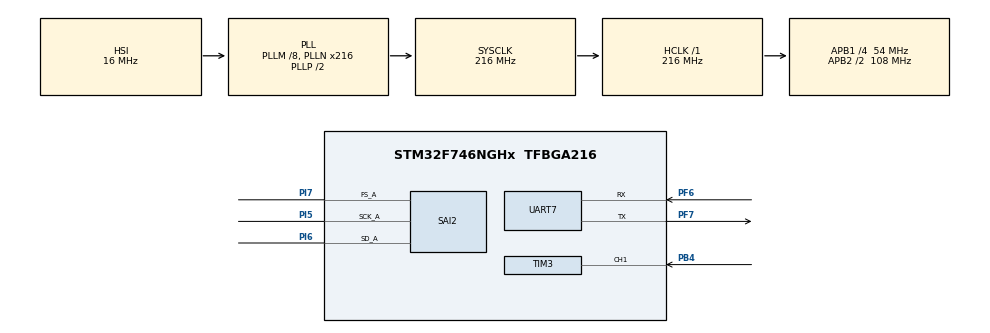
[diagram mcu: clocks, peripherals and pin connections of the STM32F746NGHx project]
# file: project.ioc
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Dma.Request0=SAI2_A
Dma.SAI2_A.0.Direction=DMA_MEMORY_TO_PERIPH
Dma.SAI2_A.0.FIFOMode=DMA_FIFOMODE_DISABLE
Dma.SAI2_A.0.Instance=DMA2_Stream4
Dma.SAI2_A.0.MemDataAlignment=DMA_MDATAALIGN_WORD
Dma.SAI2_A.0.MemInc=DMA_MINC_ENABLE
Dma.SAI2_A.0.Mode=DMA_NORMAL
Dma.SAI2_A.0.PeriphDataAlignment=DMA_PDATAALIGN_WORD
Dma.SAI2_A.0.PeriphInc=DMA_PINC_DISABLE
Dma.SAI2_A.0.Priority=DMA_PRIORITY_LOW
Mcu.Family=STM32F7
Mcu.Name=STM32F746NGHx
Mcu.Package=TFBGA216
NVIC.DMA2_Stream4_IRQn=true\:0\:0\:false\:false\:true\:false\:true
NVIC.PriorityGroup=NVIC_PRIORITYGROUP_4
PB4.Signal=S_TIM3_CH1
PF6.Mode=Asynchronous
PF6.Signal=UART7_RX
PF7.Mode=Asynchronous
PF7.Signal=UART7_TX
PI5.Mode=SAI_A_Master
PI5.Signal=SAI2_SCK_A
PI6.Mode=SAI_A_Master
PI6.Signal=SAI2_SD_A
PI7.Mode=SAI_A_Master
PI7.Signal=SAI2_FS_A
ProjectManager.HeapSize=0x200
ProjectManager.StackSize=0x400
ProjectManager.TargetToolchain=STM32CubeIDE
RCC.AHBFreq_Value=216000000
RCC.APB1CLKDivider=RCC_HCLK_DIV4
RCC.APB1Freq_Value=54000000
RCC.APB1TimFreq_Value=108000000
RCC.APB2CLKDivider=RCC_HCLK_DIV2
RCC.APB2Freq_Value=108000000
RCC.APB2TimFreq_Value=216000000
RCC.CortexFreq_Value=216000000
RCC.HCLKFreq_Value=216000000
RCC.HSE_VALUE=25000000
RCC.HSI_VALUE=16000000
RCC.LSE_VALUE=32768
RCC.PLLM=8
RCC.PLLN=216
RCC.PLLSAIN=50
RCC.PLLSourceVirtual=RCC_PLLSOURCE_HSI
RCC.SYSCLKFreq_VALUE=216000000
RCC.SYSCLKSource=RCC_SYSCLKSOURCE_PLLCLK
RCC.USBFreq_Value=216000000
RCC.VCOOutputFreq_Value=432000000
SAI2.ErrorAudioFreq-SAI_A_Master=56.25 %
SAI2.Instance-SAI_A_Master=SAI$Index_Block_A
SAI2.MClockEnable-SAI_A_Master=SAI_MASTERCLOCK_DISABLE
SAI2.RealAudioFreq-SAI_A_Master=300.0 KHz
SAI2.VirtualMode-SAI_A_Master=VM_MASTER
SH.S_TIM3_CH1.0=TIM3_CH1,Input_Capture1_from_TI1
STMicroelectronics.X-CUBE-AI.4.0.0.ApplicationCcArtificialOoIntelligenceJjApplication=ApplicationTemplate
STMicroelectronics.X-CUBE-AI.4.0.0.ArtificialOoIntelligenceJjApplication.cmp_version0=4.0.0
STMicroelectronics.X-CUBE-AI.4.0.0.ArtificialOoIntelligenceJjApplication.component0=Artificial Intelligence
STMicroelectronics.X-CUBE-AI.4.0.0.ArtificialOoIntelligenceJjApplication.description0=AI Application,Application Template
STMicroelectronics.X-CUBE-AI.4.0.0.ArtificialOoIntelligenceJjApplication.diagnostic0=This component should operate correctly.
STMicroelectronics.X-CUBE-AI.4.0.0.ArtificialOoIntelligenceJjApplication.documentation0=Documentation/index.html
STMicroelectronics.X-CUBE-AI.4.0.0.ArtificialOoIntelligenceJjApplication.group0=Application
STMicroelectronics.X-CUBE-AI.4.0.0.ArtificialOoIntelligenceJjApplication.paramName0=ApplicationCcArtificialOoIntelligenceJjApplication
STMicroelectronics.X-CUBE-AI.4.0.0.ArtificialOoIntelligenceJjApplication.sevirity0=none
STMicroelectronics.X-CUBE-AI.4.0.0.ArtificialOoIntelligenceJjApplication.variant0=ApplicationTemplate
STMicroelectronics.X-CUBE-AI.4.0.0.ArtificialOoIntelligenceJjApplication_bundle=Application
STMicroelectronics.X-CUBE-AI.4.0.0.ArtificialOoIntelligenceJjApplication_class=ArtificialOoIntelligence
STMicroelectronics.X-CUBE-AI.4.0.0.ArtificialOoIntelligenceJjApplication_name=X-CUBE-AI
STMicroelectronics.X-CUBE-AI.4.0.0.ArtificialOoIntelligenceJjApplication_size=1
STMicroelectronics.X-CUBE-AI.4.0.0.ArtificialOoIntelligenceJjApplication_vendor=STMicroelectronics
STMicroelectronics.X-CUBE-AI.4.0.0.ArtificialOoIntelligenceJjApplication_version=4.0.0
STMicroelectronics.X-CUBE-AI.4.0.0.ArtificialOoIntelligenceJjXAaCUBEAaAI.cmp_version0=4.0.0
STMicroelectronics.X-CUBE-AI.4.0.0.ArtificialOoIntelligenceJjXAaCUBEAaAI.cmp_version1=4.0.0
STMicroelectronics.X-CUBE-AI.4.0.0.ArtificialOoIntelligenceJjXAaCUBEAaAI.component0=Artificial Intelligence
STMicroelectronics.X-CUBE-AI.4.0.0.ArtificialOoIntelligenceJjXAaCUBEAaAI.component1=Artificial Intelligence
STMicroelectronics.X-CUBE-AI.4.0.0.ArtificialOoIntelligenceJjXAaCUBEAaAI.componentDoc0=nofile
STMicroelectronics.X-CUBE-AI.4.0.0.ArtificialOoIntelligenceJjXAaCUBEAaAI.description0=AI Core,Artificial Intelligence for STM32
STMicroelectronics.X-CUBE-AI.4.0.0.ArtificialOoIntelligenceJjXAaCUBEAaAI.description1=AI Application,Application Template
STMicroelectronics.X-CUBE-AI.4.0.0.ArtificialOoIntelligenceJjXAaCUBEAaAI.diagnostic0=This component should operate correctly.
STMicroelectronics.X-CUBE-AI.4.0.0.ArtificialOoIntelligenceJjXAaCUBEAaAI.diagnostic1=This component should operate correctly.
STMicroelectronics.X-CUBE-AI.4.0.0.ArtificialOoIntelligenceJjXAaCUBEAaAI.documentation0=Documentation/index.html
STMicroelectronics.X-CUBE-AI.4.0.0.ArtificialOoIntelligenceJjXAaCUBEAaAI.documentation1=Documentation/index.html
STMicroelectronics.X-CUBE-AI.4.0.0.ArtificialOoIntelligenceJjXAaCUBEAaAI.group0=Core
STMicroelectronics.X-CUBE-AI.4.0.0.ArtificialOoIntelligenceJjXAaCUBEAaAI.group1=Application
STMicroelectronics.X-CUBE-AI.4.0.0.ArtificialOoIntelligenceJjXAaCUBEAaAI.paramName0=XAaCUBEAaAICcArtificialOoIntelligenceJjCore
STMicroelectronics.X-CUBE-AI.4.0.0.ArtificialOoIntelligenceJjXAaCUBEAaAI.paramName1=ApplicationCcArtificialOoIntelligenceJjApplication
STMicroelectronics.X-CUBE-AI.4.0.0.ArtificialOoIntelligenceJjXAaCUBEAaAI.sevirity0=none
STMicroelectronics.X-CUBE-AI.4.0.0.ArtificialOoIntelligenceJjXAaCUBEAaAI.sevirity1=none
STMicroelectronics.X-CUBE-AI.4.0.0.ArtificialOoIntelligenceJjXAaCUBEAaAI.variant1=ApplicationTemplate
STMicroelectronics.X-CUBE-AI.4.0.0.ArtificialOoIntelligenceJjXAaCUBEAaAI_bundle=X-CUBE-AI
STMicroelectronics.X-CUBE-AI.4.0.0.ArtificialOoIntelligenceJjXAaCUBEAaAI_class=ArtificialOoIntelligence
STMicroelectronics.X-CUBE-AI.4.0.0.ArtificialOoIntelligenceJjXAaCUBEAaAI_name=X-CUBE-AI
STMicroelectronics.X-CUBE-AI.4.0.0.ArtificialOoIntelligenceJjXAaCUBEAaAI_size=2
STMicroelectronics.X-CUBE-AI.4.0.0.ArtificialOoIntelligenceJjXAaCUBEAaAI_vendor=STMicroelectronics
STMicroelectronics.X-CUBE-AI.4.0.0.ArtificialOoIntelligenceJjXAaCUBEAaAI_version=4.0.0
STMicroelectronics.X-CUBE-AI.4.0.0.LatestDirectoryUsed-ff25e316b0d218b1b75e30100dc37cf2b87ceea797e5b8a9c0dbcca06200be8c=/Users/andersliss/Google Drive/Dokument/Resurser/Python/50ms_30mels
STMicroelectronics.X-CUBE-AI.4.0.0.ModelActualCompression-ff25e316b0d218b1b75e30100dc37cf2b87ceea797e5b8a9c0dbcca06200be8c=0.0
STMicroelectronics.X-CUBE-AI.4.0.0.ModelCompression-ff25e316b0d218b1b75e30100dc37cf2b87ceea797e5b8a9c0dbcca06200be8c=1
STMicroelectronics.X-CUBE-AI.4.0.0.ModelFlashOccupation-ff25e316b0d218b1b75e30100dc37cf2b87ceea797e5b8a9c0dbcca06200be8c=11368
STMicroelectronics.X-CUBE-AI.4.0.0.ModelHashList=ff25e316b0d218b1b75e30100dc37cf2b87ceea797e5b8a9c0dbcca06200be8c
STMicroelectronics.X-CUBE-AI.4.0.0.ModelKind-ff25e316b0d218b1b75e30100dc37cf2b87ceea797e5b8a9c0dbcca06200be8c=KERAS
STMicroelectronics.X-CUBE-AI.4.0.0.ModelMacc-ff25e316b0d218b1b75e30100dc37cf2b87ceea797e5b8a9c0dbcca06200be8c=491910
STMicroelectronics.X-CUBE-AI.4.0.0.ModelName-ff25e316b0d218b1b75e30100dc37cf2b87ceea797e5b8a9c0dbcca06200be8c=network_multitest
STMicroelectronics.X-CUBE-AI.4.0.0.ModelNameList=network_multitest
STMicroelectronics.X-CUBE-AI.4.0.0.ModelRamOccupation-ff25e316b0d218b1b75e30100dc37cf2b87ceea797e5b8a9c0dbcca06200be8c=144000
STMicroelectronics.X-CUBE-AI.4.0.0.ModelStructureFile-ff25e316b0d218b1b75e30100dc37cf2b87ceea797e5b8a9c0dbcca06200be8c=/Users/andersliss/Google Drive/Dokument/Resurser/Python/50ms_30mels/DNN_Model.h5
STMicroelectronics.X-CUBE-AI.4.0.0.ModelType-ff25e316b0d218b1b75e30100dc37cf2b87ceea797e5b8a9c0dbcca06200be8c=Saved model
STMicroelectronics.X-CUBE-AI.4.0.0.ValidationInputFile-ff25e316b0d218b1b75e30100dc37cf2b87ceea797e5b8a9c0dbcca06200be8c=/Users/andersliss/Google Drive/Dokument/Resurser/Python/100ms_nomels/x_50ms_val.csv
STMicroelectronics.X-CUBE-AI.4.0.0.ValidationOutputFile-ff25e316b0d218b1b75e30100dc37cf2b87ceea797e5b8a9c0dbcca06200be8c=/Users/andersliss/Google Drive/Dokument/Resurser/Python/100ms_nomels/y_50ms_val.csv
STMicroelectronics.X-CUBE-AI.4.0.0.XAaCUBEAaAICcArtificialOoIntelligenceJjCore=true
STMicroelectronics.X-CUBE-AI.4.0.0_ArtificialOoIntelligenceJjApplication_RteComponent0=\#define AI_ApplicationTemplate
STMicroelectronics.X-CUBE-AI.4.0.0_ArtificialOoIntelligenceJjApplication_RteComponentsize=1
STMicroelectronics.X-CUBE-AI.4.0.0_ArtificialOoIntelligenceJjXAaCUBEAaAI_RteComponentsize=0
STMicroelectronics.X-CUBE-AI.4.0.0_MwName0=X-CUBE-AI
STMicroelectronics.X-CUBE-AI.4.0.0_MwName1=Application
STMicroelectronics.X-CUBE-AI.4.0.0_NumberOfMw=2
STMicroelectronics.X-CUBE-AI.4.0.0_description=Artificial Intelligence
STMicroelectronics.X-CUBE-AI.4.0.0_license=SLA0048.txt
TIM3.Channel-Input_Capture1_from_TI1=TIM_CHANNEL_1
VP_CRC_VS_CRC.Mode=CRC_Activate
VP_STMicroelectronics.X-CUBE-AI_VS_ArtificialOoIntelligenceJjApplication_4.0.0.Mode=ArtificialOoIntelligenceJjApplication
VP_STMicroelectronics.X-CUBE-AI_VS_ArtificialOoIntelligenceJjXAaCUBEAaAI_4.0.0.Mode=ArtificialOoIntelligenceJjXAaCUBEAaAI
VP_TIM3_VS_ClockSourceINT.Mode=Internal
board=STM32F746G-DISCO

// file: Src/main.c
/* USER CODE BEGIN Header */
/**
  ******************************************************************************
  * @file           : main.c
  * @brief          : Main program body
  ******************************************************************************
  * @attention
  *
  * <h2><center>&copy; Copyright (c) 2019 STMicroelectronics.
  * All rights reserved.</center></h2>
  *
  * This software component is licensed by ST under BSD 3-Clause license,
  * the "License"; You may not use this file except in compliance with the
  * License. You may obtain a copy of the License at:
  *                        opensource.org/licenses/BSD-3-Clause
  *
  ******************************************************************************
  */
/* USER CODE END Header */

#include "main.h"
#include "app_x-cube-ai.h"

/* USER CODE BEGIN Includes */
#include "audio_processing.h"
/* USER CODE END Includes */

CRC_HandleTypeDef hcrc;

SAI_HandleTypeDef hsai_BlockA2;
DMA_HandleTypeDef hdma_sai2_a;

TIM_HandleTypeDef htim3;

UART_HandleTypeDef huart7;

/* USER CODE BEGIN PV */
uint16_t input[buffersize] = {0};
uint16_t *pInput = &input[0];
uint16_t processbuffer[buffersize] = {0};
float32_t fftbuf[buffersize] = {0};
uint8_t check = 0;

/* USER CODE END PV */

void SystemClock_Config(void);
static void MX_GPIO_Init(void);
static void MX_DMA_Init(void);
static void MX_CRC_Init(void);
static void MX_SAI2_Init(void);
static void MX_TIM3_Init(void);
static void MX_UART7_Init(void);

int main(void)
{

  /* MCU Configuration--------------------------------------------------------*/

  /* Reset of all peripherals, Initializes the Flash interface and the Systick. */
  HAL_Init();

  /* Configure the system clock */
  SystemClock_Config();

  /* Initialize all configured peripherals */
  MX_GPIO_Init();
  MX_DMA_Init();
  MX_CRC_Init();
  MX_SAI2_Init();
  MX_TIM3_Init();
  MX_UART7_Init();
  MX_X_CUBE_AI_Init();
  /* USER CODE BEGIN 2 */

  // Initialize audio input with BSP
  BSP_AUDIO_IN_InitEx(INPUT_DEVICE_DIGITAL_MICROPHONE_2, 44100, 16, 1);
  BSP_AUDIO_IN_Record(pInput, buffersize);

  // Initializing spectrogram
  Spectro_Init();

  /* USER CODE END 2 */

  /* Infinite loop */
  while (1)
  {

    /* USER CODE BEGIN 3 */
		 // Copy input memory to processing buffer
	  memcpy(&processbuffer[0],&input[0],buffersize);

	 // Convert uint16_t to float32 for use with CMSIS
	  for (uint16_t c = 0; c < buffersize; c++)
	  {
		  fftbuf[c] = (float32_t)processbuffer[c];
	  }

	  Spectrogram_Run((float32_t *) fftbuf);
	  check = 1;
  }
  /* USER CODE END 3 */
}

void SystemClock_Config(void)
{
  RCC_OscInitTypeDef RCC_OscInitStruct = {0};
  RCC_ClkInitTypeDef RCC_ClkInitStruct = {0};
  RCC_PeriphCLKInitTypeDef PeriphClkInitStruct = {0};

  /** Configure the main internal regulator output voltage
  */
  __HAL_RCC_PWR_CLK_ENABLE();
  __HAL_PWR_VOLTAGESCALING_CONFIG(PWR_REGULATOR_VOLTAGE_SCALE1);
  /** Initializes the CPU, AHB and APB busses clocks
  */
  RCC_OscInitStruct.OscillatorType = RCC_OSCILLATORTYPE_HSI;
  RCC_OscInitStruct.HSIState = RCC_HSI_ON;
  RCC_OscInitStruct.HSICalibrationValue = RCC_HSICALIBRATION_DEFAULT;
  RCC_OscInitStruct.PLL.PLLState = RCC_PLL_ON;
  RCC_OscInitStruct.PLL.PLLSource = RCC_PLLSOURCE_HSI;
  RCC_OscInitStruct.PLL.PLLM = 8;
  RCC_OscInitStruct.PLL.PLLN = 216;
  RCC_OscInitStruct.PLL.PLLP = RCC_PLLP_DIV2;
  RCC_OscInitStruct.PLL.PLLQ = 2;
  if (HAL_RCC_OscConfig(&RCC_OscInitStruct) != HAL_OK)
  {
    Error_Handler();
  }
  /** Activate the Over-Drive mode
  */
  if (HAL_PWREx_EnableOverDrive() != HAL_OK)
  {
    Error_Handler();
  }
  /** Initializes the CPU, AHB and APB busses clocks
  */
  RCC_ClkInitStruct.ClockType = RCC_CLOCKTYPE_HCLK|RCC_CLOCKTYPE_SYSCLK
                              |RCC_CLOCKTYPE_PCLK1|RCC_CLOCKTYPE_PCLK2;
  RCC_ClkInitStruct.SYSCLKSource = RCC_SYSCLKSOURCE_PLLCLK;
  RCC_ClkInitStruct.AHBCLKDivider = RCC_SYSCLK_DIV1;
  RCC_ClkInitStruct.APB1CLKDivider = RCC_HCLK_DIV4;
  RCC_ClkInitStruct.APB2CLKDivider = RCC_HCLK_DIV2;

  if (HAL_RCC_ClockConfig(&RCC_ClkInitStruct, FLASH_LATENCY_7) != HAL_OK)
  {
    Error_Handler();
  }
  PeriphClkInitStruct.PeriphClockSelection = RCC_PERIPHCLK_UART7|RCC_PERIPHCLK_SAI2;
  PeriphClkInitStruct.PLLSAI.PLLSAIN = 50;
  PeriphClkInitStruct.PLLSAI.PLLSAIR = 2;
  PeriphClkInitStruct.PLLSAI.PLLSAIQ = 2;
  PeriphClkInitStruct.PLLSAI.PLLSAIP = RCC_PLLSAIP_DIV2;
  PeriphClkInitStruct.PLLSAIDivQ = 1;
  PeriphClkInitStruct.PLLSAIDivR = RCC_PLLSAIDIVR_2;
  PeriphClkInitStruct.Sai2ClockSelection = RCC_SAI2CLKSOURCE_PLLSAI;
  PeriphClkInitStruct.Uart7ClockSelection = RCC_UART7CLKSOURCE_PCLK1;
  if (HAL_RCCEx_PeriphCLKConfig(&PeriphClkInitStruct) != HAL_OK)
  {
    Error_Handler();
  }
}

static void MX_CRC_Init(void)
{

  hcrc.Instance = CRC;
  hcrc.Init.DefaultPolynomialUse = DEFAULT_POLYNOMIAL_ENABLE;
  hcrc.Init.DefaultInitValueUse = DEFAULT_INIT_VALUE_ENABLE;
  hcrc.Init.InputDataInversionMode = CRC_INPUTDATA_INVERSION_NONE;
  hcrc.Init.OutputDataInversionMode = CRC_OUTPUTDATA_INVERSION_DISABLE;
  hcrc.InputDataFormat = CRC_INPUTDATA_FORMAT_BYTES;
  if (HAL_CRC_Init(&hcrc) != HAL_OK)
  {
    Error_Handler();
  }

}

static void MX_SAI2_Init(void)
{

  hsai_BlockA2.Instance = SAI2_Block_A;
  hsai_BlockA2.Init.Protocol = SAI_FREE_PROTOCOL;
  hsai_BlockA2.Init.AudioMode = SAI_MODEMASTER_TX;
  hsai_BlockA2.Init.DataSize = SAI_DATASIZE_8;
  hsai_BlockA2.Init.FirstBit = SAI_FIRSTBIT_MSB;
  hsai_BlockA2.Init.ClockStrobing = SAI_CLOCKSTROBING_FALLINGEDGE;
  hsai_BlockA2.Init.Synchro = SAI_ASYNCHRONOUS;
  hsai_BlockA2.Init.OutputDrive = SAI_OUTPUTDRIVE_DISABLE;
  hsai_BlockA2.Init.NoDivider = SAI_MASTERDIVIDER_ENABLE;
  hsai_BlockA2.Init.FIFOThreshold = SAI_FIFOTHRESHOLD_EMPTY;
  hsai_BlockA2.Init.AudioFrequency = SAI_AUDIO_FREQUENCY_192K;
  hsai_BlockA2.Init.SynchroExt = SAI_SYNCEXT_DISABLE;
  hsai_BlockA2.Init.MonoStereoMode = SAI_STEREOMODE;
  hsai_BlockA2.Init.CompandingMode = SAI_NOCOMPANDING;
  hsai_BlockA2.Init.TriState = SAI_OUTPUT_NOTRELEASED;
  hsai_BlockA2.FrameInit.FrameLength = 8;
  hsai_BlockA2.FrameInit.ActiveFrameLength = 1;
  hsai_BlockA2.FrameInit.FSDefinition = SAI_FS_STARTFRAME;
  hsai_BlockA2.FrameInit.FSPolarity = SAI_FS_ACTIVE_LOW;
  hsai_BlockA2.FrameInit.FSOffset = SAI_FS_FIRSTBIT;
  hsai_BlockA2.SlotInit.FirstBitOffset = 0;
  hsai_BlockA2.SlotInit.SlotSize = SAI_SLOTSIZE_DATASIZE;
  hsai_BlockA2.SlotInit.SlotNumber = 1;
  hsai_BlockA2.SlotInit.SlotActive = 0x00000000;
  if (HAL_SAI_Init(&hsai_BlockA2) != HAL_OK)
  {
    Error_Handler();
  }

}

static void MX_TIM3_Init(void)
{

  TIM_ClockConfigTypeDef sClockSourceConfig = {0};
  TIM_MasterConfigTypeDef sMasterConfig = {0};
  TIM_IC_InitTypeDef sConfigIC = {0};

  htim3.Instance = TIM3;
  htim3.Init.Prescaler = 0;
  htim3.Init.CounterMode = TIM_COUNTERMODE_UP;
  htim3.Init.Period = 0;
  htim3.Init.ClockDivision = TIM_CLOCKDIVISION_DIV1;
  htim3.Init.AutoReloadPreload = TIM_AUTORELOAD_PRELOAD_DISABLE;
  if (HAL_TIM_Base_Init(&htim3) != HAL_OK)
  {
    Error_Handler();
  }
  sClockSourceConfig.ClockSource = TIM_CLOCKSOURCE_INTERNAL;
  if (HAL_TIM_ConfigClockSource(&htim3, &sClockSourceConfig) != HAL_OK)
  {
    Error_Handler();
  }
  if (HAL_TIM_IC_Init(&htim3) != HAL_OK)
  {
    Error_Handler();
  }
  sMasterConfig.MasterOutputTrigger = TIM_TRGO_RESET;
  sMasterConfig.MasterSlaveMode = TIM_MASTERSLAVEMODE_DISABLE;
  if (HAL_TIMEx_MasterConfigSynchronization(&htim3, &sMasterConfig) != HAL_OK)
  {
    Error_Handler();
  }
  sConfigIC.ICPolarity = TIM_INPUTCHANNELPOLARITY_RISING;
  sConfigIC.ICSelection = TIM_ICSELECTION_DIRECTTI;
  sConfigIC.ICPrescaler = TIM_ICPSC_DIV1;
  sConfigIC.ICFilter = 0;
  if (HAL_TIM_IC_ConfigChannel(&htim3, &sConfigIC, TIM_CHANNEL_1) != HAL_OK)
  {
    Error_Handler();
  }

}

static void MX_UART7_Init(void)
{

  huart7.Instance = UART7;
  huart7.Init.BaudRate = 115200;
  huart7.Init.WordLength = UART_WORDLENGTH_8B;
  huart7.Init.StopBits = UART_STOPBITS_1;
  huart7.Init.Parity = UART_PARITY_NONE;
  huart7.Init.Mode = UART_MODE_TX_RX;
  huart7.Init.HwFlowCtl = UART_HWCONTROL_NONE;
  huart7.Init.OverSampling = UART_OVERSAMPLING_16;
  huart7.Init.OneBitSampling = UART_ONE_BIT_SAMPLE_DISABLE;
  huart7.AdvancedInit.AdvFeatureInit = UART_ADVFEATURE_NO_INIT;
  if (HAL_UART_Init(&huart7) != HAL_OK)
  {
    Error_Handler();
  }

}

static void MX_DMA_Init(void)
{

  /* DMA controller clock enable */
  __HAL_RCC_DMA2_CLK_ENABLE();

  /* DMA interrupt init */
  /* DMA2_Stream4_IRQn interrupt configuration */
  HAL_NVIC_SetPriority(DMA2_Stream4_IRQn, 0, 0);
  HAL_NVIC_EnableIRQ(DMA2_Stream4_IRQn);

}

static void MX_GPIO_Init(void)
{

  /* GPIO Ports Clock Enable */
  __HAL_RCC_GPIOB_CLK_ENABLE();
  __HAL_RCC_GPIOI_CLK_ENABLE();
  __HAL_RCC_GPIOF_CLK_ENABLE();

}

void Error_Handler(void)
{
}

/************************ (C) COPYRIGHT STMicroelectronics *****END OF FILE****/
